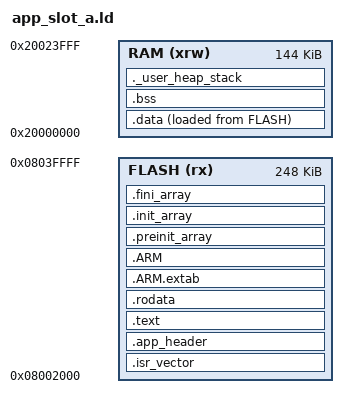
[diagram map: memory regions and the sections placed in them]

/**
 ******************************************************************************
 * @file      app_slot_a.ld
 * @brief     Linker script for App Slot A (STM32G0B1RET6, 248KB Flash)
 *            Vector table at 0x08002000, runs after Bootloader.
 *            Auto-generated by Hardware2Code
 ******************************************************************************
 */

ENTRY(Reset_Handler)

_estack = ORIGIN(RAM) + LENGTH(RAM);

_Min_Heap_Size = 0x2000;
_Min_Stack_Size = 0x800;

/* VTOR 偏移量（C 代码中设置 SCB->VTOR 时使用） */
__vtor_offset__ = 0x00002000;

MEMORY
{
  RAM    (xrw)    : ORIGIN = 0x20000000,   LENGTH = 144K
  FLASH  (rx)     : ORIGIN = 0x08002000,   LENGTH = 248K
}

SECTIONS
{
  .isr_vector :
  {
    . = ALIGN(4);
    KEEP(*(.isr_vector))
    . = ALIGN(4);
  } >FLASH

  /* 固件镜像头部（紧随向量表，偏移 0xC0, 12 字节）
     Bootloader 从 slot_start + 0xC0 读取此头部。
     格式: [image_size(4B) | CRC32(4B) | magic(4B)] */
  .app_header :
  {
    . = ALIGN(4);
    LONG(0xFFFFFFFF);         /* 镜像大小占位，编译后由 patch_crc.py 填充 */
    LONG(0xFFFFFFFF);         /* CRC32 占位，编译后由 patch_crc.py 填充 */
    LONG(0x4841436B);         /* magic "H2Ck"，标识有效头部 */
  } >FLASH

  .text :
  {
    . = ALIGN(4);
    *(.text)
    *(.text*)
    *(.glue_7)
    *(.glue_7t)
    *(.eh_frame)

    KEEP (*(.init))
    KEEP (*(.fini))

    . = ALIGN(4);
    _etext = .;
  } >FLASH

  .rodata :
  {
    . = ALIGN(4);
    *(.rodata)
    *(.rodata*)
    . = ALIGN(4);
  } >FLASH

  .ARM.extab (READONLY) :
  {
    . = ALIGN(4);
    *(.ARM.extab* .gnu.linkonce.armextab.*)
    . = ALIGN(4);
  } >FLASH

  .ARM (READONLY) :
  {
    . = ALIGN(4);
    __exidx_start = .;
    *(.ARM.exidx*)
    __exidx_end = .;
    . = ALIGN(4);
  } >FLASH

  .preinit_array (READONLY) :
  {
    . = ALIGN(4);
    PROVIDE_HIDDEN (__preinit_array_start = .);
    KEEP (*(.preinit_array*))
    PROVIDE_HIDDEN (__preinit_array_end = .);
    . = ALIGN(4);
  } >FLASH

  .init_array (READONLY) :
  {
    . = ALIGN(4);
    PROVIDE_HIDDEN (__init_array_start = .);
    KEEP (*(SORT(.init_array.*)))
    KEEP (*(.init_array*))
    PROVIDE_HIDDEN (__init_array_end = .);
    . = ALIGN(4);
  } >FLASH

  .fini_array (READONLY) :
  {
    . = ALIGN(4);
    PROVIDE_HIDDEN (__fini_array_start = .);
    KEEP (*(SORT(.fini_array.*)))
    KEEP (*(.fini_array*))
    PROVIDE_HIDDEN (__fini_array_end = .);
    . = ALIGN(4);
  } >FLASH

  _sidata = LOADADDR(.data);

  .data :
  {
    . = ALIGN(4);
    _sdata = .;
    *(.data)
    *(.data*)
    . = ALIGN(4);
    _edata = .;
  } >RAM AT> FLASH

  . = ALIGN(4);
  .bss :
  {
    _sbss = .;
    __bss_start__ = _sbss;
    *(.bss)
    *(.bss*)
    *(COMMON)
    . = ALIGN(4);
    _ebss = .;
    __bss_end__ = _ebss;
  } >RAM

  ._user_heap_stack :
  {
    . = ALIGN(8);
    PROVIDE ( end = . );
    PROVIDE ( _end = . );
    . = . + _Min_Heap_Size;
    . = . + _Min_Stack_Size;
    . = ALIGN(8);
  } >RAM

  /DISCARD/ :
  {
    libc.a ( * )
    libm.a ( * )
    libgcc.a ( * )
  }

  .ARM.attributes 0 : { *(.ARM.attributes) }
}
